VERSION ""

NS_ :

BS_:

BU_: Amperes VoltTemp_7 VoltTemp_6 VoltTemp_5 VoltTemp_4 VoltTemp_3 VoltTemp_2 VoltTemp_1 VoltTemp_0 BPS_Leader
VAL_TABLE_ BPS_Fault_Type 16 "Discharging Overcurrent" 15 "Charging Overcurrent" 14 "Estop 3" 13 "Estop 2" 12 "Estop 1" 11 "Array Pchg Contactor Sense" 10 "Array Contactor Sense" 9 "HV Minus Contactor Sense" 8 "HV Plus Contactor Sense" 7 "Watchdog" 6 "Array Precharge Timeout" 5 "Elcon" 4 "Overtemperature" 3 "Regen" 2 "Undervoltage" 1 "Overvoltage" 0 "No Fault" ;

BO_ 3221225472 VECTOR__INDEPENDENT_SIG_MSG: 0 Vector__XXX
 SG_ BPS_VoltTemp_ID : 0|3@1+ (1,0) [0|7] "" Vector__XXX
 SG_ BPS_Tap_idx : 0|5@1+ (1,0) [0|31] "" Vector__XXX
 SG_ BPS_VoltTemp_ID : 0|3@1+ (1,0) [0|7] "" Vector__XXX
 SG_ BPS_Temperature_Tap_Fault : 0|1@1+ (1,0) [0|0] "" Vector__XXX
 SG_ BPS_VoltTemp_BQ_Fault : 0|1@1+ (1,0) [0|0] "" Vector__XXX
 SG_ BPS_Temperature_Tap_RawV : 0|16@1+ (0.001,0) [0|65.535] "V" Vector__XXX
 SG_ BPS_Temperature_Tap_Data : 0|16@1- (0.01,0) [-327.68|327.67] "C" Vector__XXX
 SG_ BPS_Voltage_Tap_Data : 0|16@1+ (0.001,0) [0|65.535] "V" Vector__XXX
 SG_ BPS_Tap_idx : 0|5@1+ (1,0) [0|31] "" Vector__XXX
 SG_ BPS_Temperature_Tap_Fault : 0|1@1+ (1,0) [0|0] "" Vector__XXX
 SG_ BPS_VoltTemp_BQ_Fault : 0|1@1+ (1,0) [0|0] "" Vector__XXX
 SG_ BPS_Temperature_Tap_RawV : 0|16@1+ (0.001,0) [0|65.535] "V" Vector__XXX
 SG_ BPS_Temperature_Tap_Data : 0|16@1- (0.01,0) [-327.68|327.67] "C" Vector__XXX
 SG_ BPS_Voltage_Tap_Data : 0|16@1+ (0.001,0) [0|65.535] "V" Vector__XXX
 SG_ BPS_Tap_idx : 0|5@1+ (1,0) [0|31] "" Vector__XXX
 SG_ BPS_Temperature_Tap_Fault : 0|1@1+ (1,0) [0|0] "" Vector__XXX
 SG_ BPS_VoltTemp_BQ_Fault : 0|1@1+ (1,0) [0|0] "" Vector__XXX
 SG_ BPS_Temperature_Tap_RawV : 0|16@1+ (0.001,0) [0|65.535] "V" Vector__XXX
 SG_ BPS_Temperature_Tap_Data : 0|16@1- (0.01,0) [-327.68|327.67] "C" Vector__XXX
 SG_ BPS_Voltage_Tap_Data : 0|16@1+ (0.001,0) [0|65.535] "V" Vector__XXX
 SG_ BPS_Tap_idx : 0|5@1+ (1,0) [0|31] "" Vector__XXX
 SG_ BPS_Temperature_Tap_Fault : 0|1@1+ (1,0) [0|0] "" Vector__XXX
 SG_ BPS_VoltTemp_BQ_Fault : 0|1@1+ (1,0) [0|0] "" Vector__XXX
 SG_ BPS_Temperature_Tap_RawV : 0|16@1+ (0.001,0) [0|65.535] "V" Vector__XXX
 SG_ BPS_Temperature_Tap_Data : 0|16@1- (0.01,0) [-327.68|327.67] "C" Vector__XXX
 SG_ BPS_Voltage_Tap_Data : 0|16@1+ (0.001,0) [0|65.535] "V" Vector__XXX
 SG_ BPS_Tap_idx : 0|5@1+ (1,0) [0|31] "" Vector__XXX
 SG_ BPS_Temperature_Tap_Fault : 0|1@1+ (1,0) [0|0] "" Vector__XXX
 SG_ BPS_VoltTemp_BQ_Fault : 0|1@1+ (1,0) [0|0] "" Vector__XXX
 SG_ BPS_Temperature_Tap_RawV : 0|16@1+ (0.001,0) [0|65.535] "V" Vector__XXX
 SG_ BPS_Temperature_Tap_Data : 0|16@1- (0.01,0) [-327.68|327.67] "C" Vector__XXX
 SG_ BPS_Voltage_Tap_Data : 0|16@1+ (0.001,0) [0|65.535] "V" Vector__XXX
 SG_ BPS_Tap_idx : 0|5@1+ (1,0) [0|31] "" Vector__XXX
 SG_ BPS_Temperature_Tap_Fault : 0|1@1+ (1,0) [0|0] "" Vector__XXX
 SG_ BPS_VoltTemp_BQ_Fault : 0|1@1+ (1,0) [0|0] "" Vector__XXX
 SG_ BPS_Temperature_Tap_RawV : 0|16@1+ (0.001,0) [0|65.535] "V" Vector__XXX
 SG_ BPS_Temperature_Tap_Data : 0|16@1- (0.01,0) [-327.68|327.67] "C" Vector__XXX
 SG_ BPS_Voltage_Tap_Data : 0|16@1+ (0.001,0) [0|65.535] "V" Vector__XXX
 SG_ BPS_Tap_idx : 0|5@1+ (1,0) [0|31] "" Vector__XXX
 SG_ BPS_Temperature_Tap_Fault : 0|1@1+ (1,0) [0|0] "" Vector__XXX
 SG_ BPS_VoltTemp_BQ_Fault : 0|1@1+ (1,0) [0|0] "" Vector__XXX
 SG_ BPS_Temperature_Tap_RawV : 0|16@1+ (0.001,0) [0|65.535] "V" Vector__XXX
 SG_ BPS_Temperature_Tap_Data : 0|16@1- (0.01,0) [-327.68|327.67] "C" Vector__XXX
 SG_ BPS_Voltage_Tap_Data : 0|16@1+ (0.001,0) [0|65.535] "V" Vector__XXX
 SG_ BPS_Tap_idx : 0|5@1+ (1,0) [0|31] "" Vector__XXX

BO_ 23 BPS_Temperature_Arr_7: 6 Vector__XXX
 SG_ BPS_Temperature_Tap_Fault : 5|3@1+ (1,0) [0|0] "" Vector__XXX
 SG_ BPS_Temperature_Tap_RawV : 40|16@1+ (0.001,0) [0|65.535] "V" Vector__XXX
 SG_ BPS_Temperature_Tap_Data : 8|32@1- (0.001,0) [-2147483.648|2147483.647] "C" Vector__XXX
 SG_ BPS_Tap_idx : 0|5@1+ (1,0) [0|31] "" Vector__XXX

BO_ 22 BPS_Temperature_Arr_6: 6 Vector__XXX
 SG_ BPS_Temperature_Tap_Fault : 5|3@1+ (1,0) [0|0] "" Vector__XXX
 SG_ BPS_Temperature_Tap_RawV : 40|16@1+ (0.001,0) [0|65.535] "V" Vector__XXX
 SG_ BPS_Temperature_Tap_Data : 8|32@1- (0.001,0) [-2147483.648|2147483.647] "C" Vector__XXX
 SG_ BPS_Tap_idx : 0|5@1+ (1,0) [0|31] "" Vector__XXX

BO_ 21 BPS_Temperature_Arr_5: 6 Vector__XXX
 SG_ BPS_Temperature_Tap_Fault : 5|3@1+ (1,0) [0|0] "" Vector__XXX
 SG_ BPS_Temperature_Tap_RawV : 40|16@1+ (0.001,0) [0|65.535] "V" Vector__XXX
 SG_ BPS_Temperature_Tap_Data : 8|32@1- (0.001,0) [-2147483.648|2147483.647] "C" Vector__XXX
 SG_ BPS_Tap_idx : 0|5@1+ (1,0) [0|31] "" Vector__XXX

BO_ 20 BPS_Temperature_Arr_4: 6 Vector__XXX
 SG_ BPS_Temperature_Tap_Fault : 5|3@1+ (1,0) [0|0] "" Vector__XXX
 SG_ BPS_Temperature_Tap_RawV : 40|16@1+ (0.001,0) [0|65.535] "V" Vector__XXX
 SG_ BPS_Temperature_Tap_Data : 8|32@1- (0.001,0) [-2147483.648|2147483.647] "C" Vector__XXX
 SG_ BPS_Tap_idx : 0|5@1+ (1,0) [0|31] "" Vector__XXX

BO_ 19 BPS_Temperature_Arr_3: 6 Vector__XXX
 SG_ BPS_Temperature_Tap_Fault : 5|3@1+ (1,0) [0|0] "" Vector__XXX
 SG_ BPS_Temperature_Tap_RawV : 40|16@1+ (0.001,0) [0|65.535] "V" Vector__XXX
 SG_ BPS_Temperature_Tap_Data : 8|32@1- (0.001,0) [-2147483.648|2147483.647] "C" Vector__XXX
 SG_ BPS_Tap_idx : 0|5@1+ (1,0) [0|31] "" Vector__XXX

BO_ 18 BPS_Temperature_Arr_2: 6 Vector__XXX
 SG_ BPS_Temperature_Tap_Fault : 5|3@1+ (1,0) [0|0] "" Vector__XXX
 SG_ BPS_Temperature_Tap_RawV : 40|16@1+ (0.001,0) [0|65.535] "V" Vector__XXX
 SG_ BPS_Temperature_Tap_Data : 8|32@1- (0.001,0) [-2147483.648|2147483.647] "C" Vector__XXX
 SG_ BPS_Tap_idx : 0|5@1+ (1,0) [0|31] "" Vector__XXX

BO_ 17 BPS_Temperature_Arr_1: 6 Vector__XXX
 SG_ BPS_Temperature_Tap_Fault : 5|3@1+ (1,0) [0|0] "" Vector__XXX
 SG_ BPS_Temperature_Tap_RawV : 40|16@1+ (0.001,0) [0|65.535] "V" Vector__XXX
 SG_ BPS_Temperature_Tap_Data : 8|32@1- (0.001,0) [-2147483.648|2147483.647] "C" Vector__XXX
 SG_ BPS_Tap_idx : 0|5@1+ (1,0) [0|31] "" Vector__XXX

BO_ 16 BPS_Temperature_Arr_0: 6 Vector__XXX
 SG_ BPS_Temperature_Tap_Fault : 5|3@1+ (1,0) [0|0] "" Vector__XXX
 SG_ BPS_Temperature_Tap_RawV : 40|16@1+ (0.001,0) [0|65.535] "V" Vector__XXX
 SG_ BPS_Temperature_Tap_Data : 8|32@1- (0.001,0) [-2147483.648|2147483.647] "C" Vector__XXX
 SG_ BPS_Tap_idx : 0|5@1+ (1,0) [0|31] "" Vector__XXX

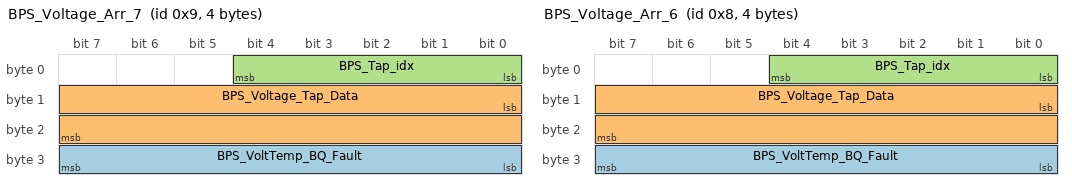
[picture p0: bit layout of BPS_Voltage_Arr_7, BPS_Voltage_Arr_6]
BO_ 9 BPS_Voltage_Arr_7: 4 Vector__XXX
 SG_ BPS_VoltTemp_BQ_Fault : 24|8@1+ (1,0) [0|0] "" Vector__XXX
 SG_ BPS_Voltage_Tap_Data : 8|16@1+ (0.001,0) [0|65.535] "V" Vector__XXX
 SG_ BPS_Tap_idx : 0|5@1+ (1,0) [0|31] "" Vector__XXX

BO_ 8 BPS_Voltage_Arr_6: 4 Vector__XXX
 SG_ BPS_VoltTemp_BQ_Fault : 24|8@1+ (1,0) [0|0] "" Vector__XXX
 SG_ BPS_Voltage_Tap_Data : 8|16@1+ (0.001,0) [0|65.535] "V" Vector__XXX
 SG_ BPS_Tap_idx : 0|5@1+ (1,0) [0|31] "" Vector__XXX

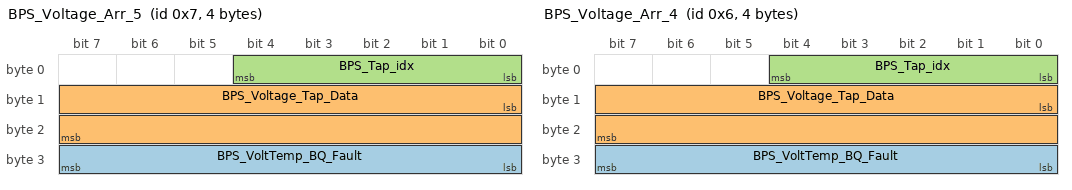
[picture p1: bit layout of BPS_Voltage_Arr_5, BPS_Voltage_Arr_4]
BO_ 7 BPS_Voltage_Arr_5: 4 Vector__XXX
 SG_ BPS_VoltTemp_BQ_Fault : 24|8@1+ (1,0) [0|0] "" Vector__XXX
 SG_ BPS_Voltage_Tap_Data : 8|16@1+ (0.001,0) [0|65.535] "V" Vector__XXX
 SG_ BPS_Tap_idx : 0|5@1+ (1,0) [0|31] "" Vector__XXX

BO_ 6 BPS_Voltage_Arr_4: 4 Vector__XXX
 SG_ BPS_VoltTemp_BQ_Fault : 24|8@1+ (1,0) [0|0] "" Vector__XXX
 SG_ BPS_Voltage_Tap_Data : 8|16@1+ (0.001,0) [0|65.535] "V" Vector__XXX
 SG_ BPS_Tap_idx : 0|5@1+ (1,0) [0|31] "" Vector__XXX

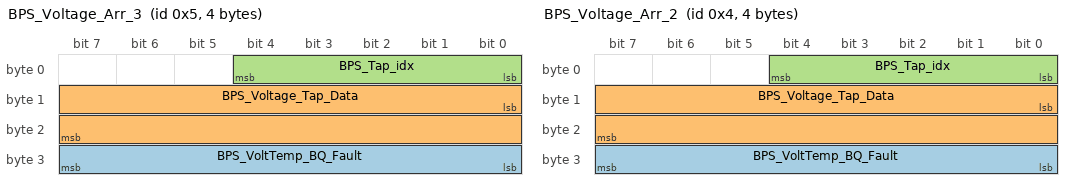
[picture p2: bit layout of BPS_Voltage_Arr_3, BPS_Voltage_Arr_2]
BO_ 5 BPS_Voltage_Arr_3: 4 Vector__XXX
 SG_ BPS_VoltTemp_BQ_Fault : 24|8@1+ (1,0) [0|0] "" Vector__XXX
 SG_ BPS_Voltage_Tap_Data : 8|16@1+ (0.001,0) [0|65.535] "V" Vector__XXX
 SG_ BPS_Tap_idx : 0|5@1+ (1,0) [0|31] "" Vector__XXX

BO_ 4 BPS_Voltage_Arr_2: 4 Vector__XXX
 SG_ BPS_VoltTemp_BQ_Fault : 24|8@1+ (1,0) [0|0] "" Vector__XXX
 SG_ BPS_Voltage_Tap_Data : 8|16@1+ (0.001,0) [0|65.535] "V" Vector__XXX
 SG_ BPS_Tap_idx : 0|5@1+ (1,0) [0|31] "" Vector__XXX

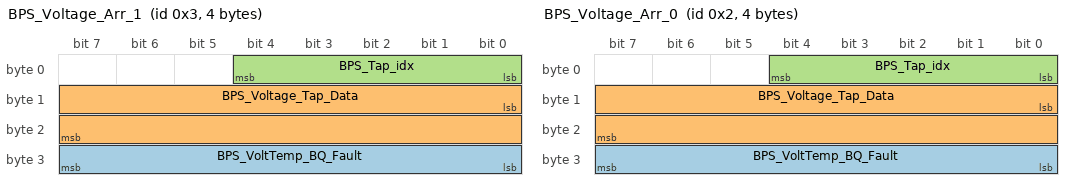
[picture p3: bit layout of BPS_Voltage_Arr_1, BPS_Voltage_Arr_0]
BO_ 3 BPS_Voltage_Arr_1: 4 Vector__XXX
 SG_ BPS_VoltTemp_BQ_Fault : 24|8@1+ (1,0) [0|0] "" Vector__XXX
 SG_ BPS_Voltage_Tap_Data : 8|16@1+ (0.001,0) [0|65.535] "V" Vector__XXX
 SG_ BPS_Tap_idx : 0|5@1+ (1,0) [0|31] "" Vector__XXX

BO_ 32 BPS_Precharge_Voltages: 6 BPS_Leader
 SG_ Precharge_Battery_Voltage : 0|24@1+ (0.001,0) [0|16777.215] "V" Vector__XXX
 SG_ Precharge_Array_Voltage : 24|24@1+ (0.001,0) [0|16777.215] "V" Vector__XXX

BO_ 2 BPS_Voltage_Arr_0: 4 VoltTemp_0
 SG_ BPS_VoltTemp_BQ_Fault : 24|8@1+ (1,0) [0|0] "" Vector__XXX
 SG_ BPS_Voltage_Tap_Data : 8|16@1+ (0.001,0) [0|65.535] "V" Vector__XXX
 SG_ BPS_Tap_idx : 0|5@1+ (1,0) [0|31] "" Vector__XXX

BO_ 10 BPS_Pack_Current: 5 Amperes
 SG_ Main_Battery_Current_RawV : 24|16@1+ (0.001,0) [0|65.535] "V" Vector__XXX
 SG_ Main_Battery_Current : 0|24@1- (0.001,0) [-8388.608|8388.607] "A" Vector__XXX

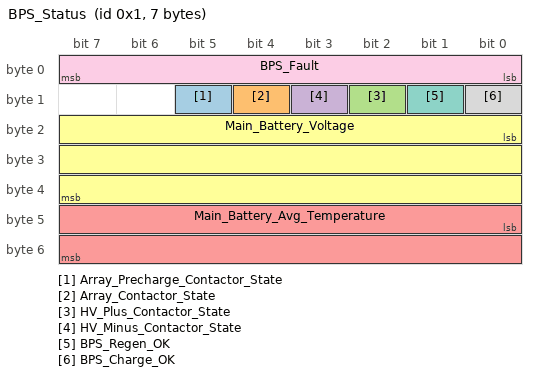
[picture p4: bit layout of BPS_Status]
BO_ 1 BPS_Status: 7 BPS_Leader
 SG_ Array_Precharge_Contactor_State : 13|1@1+ (1,0) [0|0] "" Vector__XXX
 SG_ Array_Contactor_State : 12|1@1+ (1,0) [0|0] "" Vector__XXX
 SG_ HV_Plus_Contactor_State : 10|1@1+ (1,0) [0|0] "" Vector__XXX
 SG_ HV_Minus_Contactor_State : 11|1@1+ (1,0) [0|0] "" Vector__XXX
 SG_ Main_Battery_Avg_Temperature : 40|16@1- (0.01,0) [-327.68|327.67] "" Vector__XXX
 SG_ Main_Battery_Voltage : 16|24@1+ (0.001,0) [0|16777.215] "V" Vector__XXX
 SG_ BPS_Regen_OK : 9|1@1+ (1,0) [0|0] "" Vector__XXX
 SG_ BPS_Charge_OK : 8|1@1+ (1,0) [0|0] "" Vector__XXX
 SG_ BPS_Fault : 0|8@1+ (1,0) [0|0] "" Vector__XXX

CM_ BO_ 3221225472 "This is a message for not used signals, created by Vector CANdb++ DBC OLE DB Provider.";
CM_ SG_ 3221225472 BPS_VoltTemp_ID "BPS VoltTemp IDBPS VoltTemp ID";
CM_ SG_ 3221225472 BPS_Tap_idx "BPS Voltage/Temperature Tap ID (4 taps per VoltTemp)";
CM_ SG_ 3221225472 BPS_Temperature_Tap_Fault "VoltTemp Temperature Tap Fault State (0 no fault, 1 fault)";
CM_ SG_ 3221225472 BPS_VoltTemp_BQ_Fault "VoltTemp BQ Fault State (0 no fault, 1 fault)";
CM_ SG_ 3221225472 BPS_Temperature_Tap_RawV "Raw thermistor voltage measurement for the specified VoltTemp and Tap ID";
CM_ SG_ 3221225472 BPS_Temperature_Tap_Data "Temperature tap measurement for the specified VoltTemp and Tap ID";
CM_ SG_ 3221225472 BPS_Voltage_Tap_Data "Voltage tap measurement for the specified VoltTemp and Tap ID";
CM_ SG_ 3221225472 BPS_Tap_idx "BPS Voltage/Temperature Tap ID (4 taps per VoltTemp)";
CM_ SG_ 3221225472 BPS_Temperature_Tap_Fault "VoltTemp Temperature Tap Fault State (0 no fault, 1 fault)";
CM_ SG_ 3221225472 BPS_VoltTemp_BQ_Fault "VoltTemp BQ Fault State (0 no fault, 1 fault)";
CM_ SG_ 3221225472 BPS_Temperature_Tap_RawV "Raw thermistor voltage measurement for the specified VoltTemp and Tap ID";
CM_ SG_ 3221225472 BPS_Temperature_Tap_Data "Temperature tap measurement for the specified VoltTemp and Tap ID";
CM_ SG_ 3221225472 BPS_Voltage_Tap_Data "Voltage tap measurement for the specified VoltTemp and Tap ID";
CM_ SG_ 3221225472 BPS_Tap_idx "BPS Voltage/Temperature Tap ID (4 taps per VoltTemp)";
CM_ SG_ 3221225472 BPS_Temperature_Tap_Fault "VoltTemp Temperature Tap Fault State (0 no fault, 1 fault)";
CM_ SG_ 3221225472 BPS_VoltTemp_BQ_Fault "VoltTemp BQ Fault State (0 no fault, 1 fault)";
CM_ SG_ 3221225472 BPS_Temperature_Tap_RawV "Raw thermistor voltage measurement for the specified VoltTemp and Tap ID";
CM_ SG_ 3221225472 BPS_Temperature_Tap_Data "Temperature tap measurement for the specified VoltTemp and Tap ID";
CM_ SG_ 3221225472 BPS_Voltage_Tap_Data "Voltage tap measurement for the specified VoltTemp and Tap ID";
CM_ SG_ 3221225472 BPS_Tap_idx "BPS Voltage/Temperature Tap ID (4 taps per VoltTemp)";
CM_ SG_ 3221225472 BPS_Temperature_Tap_Fault "VoltTemp Temperature Tap Fault State (0 no fault, 1 fault)";
CM_ SG_ 3221225472 BPS_VoltTemp_BQ_Fault "VoltTemp BQ Fault State (0 no fault, 1 fault)";
CM_ SG_ 3221225472 BPS_Temperature_Tap_RawV "Raw thermistor voltage measurement for the specified VoltTemp and Tap ID";
CM_ SG_ 3221225472 BPS_Temperature_Tap_Data "Temperature tap measurement for the specified VoltTemp and Tap ID";
CM_ SG_ 3221225472 BPS_Voltage_Tap_Data "Voltage tap measurement for the specified VoltTemp and Tap ID";
CM_ SG_ 3221225472 BPS_Tap_idx "BPS Voltage/Temperature Tap ID (4 taps per VoltTemp)";
CM_ SG_ 3221225472 BPS_Temperature_Tap_Fault "VoltTemp Temperature Tap Fault State (0 no fault, 1 fault)";
CM_ SG_ 3221225472 BPS_VoltTemp_BQ_Fault "VoltTemp BQ Fault State (0 no fault, 1 fault)";
CM_ SG_ 3221225472 BPS_Temperature_Tap_RawV "Raw thermistor voltage measurement for the specified VoltTemp and Tap ID";
CM_ SG_ 3221225472 BPS_Temperature_Tap_Data "Temperature tap measurement for the specified VoltTemp and Tap ID";
CM_ SG_ 3221225472 BPS_Voltage_Tap_Data "Voltage tap measurement for the specified VoltTemp and Tap ID";
CM_ SG_ 3221225472 BPS_Tap_idx "BPS Voltage/Temperature Tap ID (4 taps per VoltTemp)";
CM_ SG_ 3221225472 BPS_Temperature_Tap_Fault "VoltTemp Temperature Tap Fault State (0 no fault, 1 fault)";
CM_ SG_ 3221225472 BPS_VoltTemp_BQ_Fault "VoltTemp BQ Fault State (0 no fault, 1 fault)";
CM_ SG_ 3221225472 BPS_Temperature_Tap_RawV "Raw thermistor voltage measurement for the specified VoltTemp and Tap ID";
CM_ SG_ 3221225472 BPS_Temperature_Tap_Data "Temperature tap measurement for the specified VoltTemp and Tap ID";
CM_ SG_ 3221225472 BPS_Voltage_Tap_Data "Voltage tap measurement for the specified VoltTemp and Tap ID";
CM_ SG_ 3221225472 BPS_Tap_idx "BPS Voltage/Temperature Tap ID (4 taps per VoltTemp)";
CM_ SG_ 3221225472 BPS_Temperature_Tap_Fault "VoltTemp Temperature Tap Fault State (0 no fault, 1 fault)";
CM_ SG_ 3221225472 BPS_VoltTemp_BQ_Fault "VoltTemp BQ Fault State (0 no fault, 1 fault)";
CM_ SG_ 3221225472 BPS_Temperature_Tap_RawV "Raw thermistor voltage measurement for the specified VoltTemp and Tap ID";
CM_ SG_ 3221225472 BPS_Temperature_Tap_Data "Temperature tap measurement for the specified VoltTemp and Tap ID";
CM_ SG_ 3221225472 BPS_Voltage_Tap_Data "Voltage tap measurement for the specified VoltTemp and Tap ID";
CM_ SG_ 3221225472 BPS_Tap_idx "BPS Voltage/Temperature Tap ID (4 taps per VoltTemp)";
CM_ SG_ 23 BPS_Temperature_Tap_Fault "VoltTemp Temperature Tap Fault State (0 no fault, 1 fault)";
CM_ SG_ 23 BPS_Temperature_Tap_RawV "Raw thermistor voltage measurement for the specified VoltTemp and Tap ID";
CM_ SG_ 23 BPS_Temperature_Tap_Data "Temperature tap measurement for the specified VoltTemp and Tap ID";
CM_ SG_ 23 BPS_Tap_idx "BPS Voltage/Temperature Tap ID (4 taps per VoltTemp)";
CM_ SG_ 22 BPS_Temperature_Tap_Fault "VoltTemp Temperature Tap Fault State (0 no fault, 1 fault)";
CM_ SG_ 22 BPS_Temperature_Tap_RawV "Raw thermistor voltage measurement for the specified VoltTemp and Tap ID";
CM_ SG_ 22 BPS_Temperature_Tap_Data "Temperature tap measurement for the specified VoltTemp and Tap ID";
CM_ SG_ 22 BPS_Tap_idx "BPS Voltage/Temperature Tap ID (4 taps per VoltTemp)";
CM_ SG_ 21 BPS_Temperature_Tap_Fault "VoltTemp Temperature Tap Fault State (0 no fault, 1 fault)";
CM_ SG_ 21 BPS_Temperature_Tap_RawV "Raw thermistor voltage measurement for the specified VoltTemp and Tap ID";
CM_ SG_ 21 BPS_Temperature_Tap_Data "Temperature tap measurement for the specified VoltTemp and Tap ID";
CM_ SG_ 21 BPS_Tap_idx "BPS Voltage/Temperature Tap ID (4 taps per VoltTemp)";
CM_ SG_ 20 BPS_Temperature_Tap_Fault "VoltTemp Temperature Tap Fault State (0 no fault, 1 fault)";
CM_ SG_ 20 BPS_Temperature_Tap_RawV "Raw thermistor voltage measurement for the specified VoltTemp and Tap ID";
CM_ SG_ 20 BPS_Temperature_Tap_Data "Temperature tap measurement for the specified VoltTemp and Tap ID";
CM_ SG_ 20 BPS_Tap_idx "BPS Voltage/Temperature Tap ID (4 taps per VoltTemp)";
CM_ SG_ 19 BPS_Temperature_Tap_Fault "VoltTemp Temperature Tap Fault State (0 no fault, 1 fault)";
CM_ SG_ 19 BPS_Temperature_Tap_RawV "Raw thermistor voltage measurement for the specified VoltTemp and Tap ID";
CM_ SG_ 19 BPS_Temperature_Tap_Data "Temperature tap measurement for the specified VoltTemp and Tap ID";
CM_ SG_ 19 BPS_Tap_idx "BPS Voltage/Temperature Tap ID (4 taps per VoltTemp)";
CM_ SG_ 18 BPS_Temperature_Tap_Fault "VoltTemp Temperature Tap Fault State (0 no fault, 1 fault)";
CM_ SG_ 18 BPS_Temperature_Tap_RawV "Raw thermistor voltage measurement for the specified VoltTemp and Tap ID";
CM_ SG_ 18 BPS_Temperature_Tap_Data "Temperature tap measurement for the specified VoltTemp and Tap ID";
CM_ SG_ 18 BPS_Tap_idx "BPS Voltage/Temperature Tap ID (4 taps per VoltTemp)";
CM_ SG_ 17 BPS_Temperature_Tap_Fault "VoltTemp Temperature Tap Fault State (0 no fault, 1 fault)";
CM_ SG_ 17 BPS_Temperature_Tap_RawV "Raw thermistor voltage measurement for the specified VoltTemp and Tap ID";
CM_ SG_ 17 BPS_Temperature_Tap_Data "Temperature tap measurement for the specified VoltTemp and Tap ID";
CM_ SG_ 17 BPS_Tap_idx "BPS Voltage/Temperature Tap ID (4 taps per VoltTemp)";
CM_ SG_ 16 BPS_Temperature_Tap_Fault "VoltTemp Temperature Tap Fault State (0 no fault, 1 fault)";
CM_ SG_ 16 BPS_Temperature_Tap_RawV "Raw thermistor voltage measurement for the specified VoltTemp and Tap ID";
CM_ SG_ 16 BPS_Temperature_Tap_Data "Temperature tap measurement for the specified VoltTemp and Tap ID";
CM_ SG_ 16 BPS_Tap_idx "BPS Voltage/Temperature Tap ID (4 taps per VoltTemp)";
CM_ SG_ 9 BPS_VoltTemp_BQ_Fault "VoltTemp BQ Fault State (0 no fault, 1 fault)";
CM_ SG_ 9 BPS_Voltage_Tap_Data "Voltage tap measurement for the specified VoltTemp and Tap ID";
CM_ SG_ 9 BPS_Tap_idx "BPS Voltage/Temperature Tap ID (4 taps per VoltTemp)";
CM_ SG_ 8 BPS_VoltTemp_BQ_Fault "VoltTemp BQ Fault State (0 no fault, 1 fault)";
CM_ SG_ 8 BPS_Voltage_Tap_Data "Voltage tap measurement for the specified VoltTemp and Tap ID";
CM_ SG_ 8 BPS_Tap_idx "BPS Voltage/Temperature Tap ID (4 taps per VoltTemp)";
CM_ SG_ 7 BPS_VoltTemp_BQ_Fault "VoltTemp BQ Fault State (0 no fault, 1 fault)";
CM_ SG_ 7 BPS_Voltage_Tap_Data "Voltage tap measurement for the specified VoltTemp and Tap ID";
CM_ SG_ 7 BPS_Tap_idx "BPS Voltage/Temperature Tap ID (4 taps per VoltTemp)";
CM_ SG_ 6 BPS_VoltTemp_BQ_Fault "VoltTemp BQ Fault State (0 no fault, 1 fault)";
CM_ SG_ 6 BPS_Voltage_Tap_Data "Voltage tap measurement for the specified VoltTemp and Tap ID";
CM_ SG_ 6 BPS_Tap_idx "BPS Voltage/Temperature Tap ID (4 taps per VoltTemp)";
CM_ SG_ 5 BPS_VoltTemp_BQ_Fault "VoltTemp BQ Fault State (0 no fault, 1 fault)";
CM_ SG_ 5 BPS_Voltage_Tap_Data "Voltage tap measurement for the specified VoltTemp and Tap ID";
CM_ SG_ 5 BPS_Tap_idx "BPS Voltage/Temperature Tap ID (4 taps per VoltTemp)";
CM_ SG_ 4 BPS_VoltTemp_BQ_Fault "VoltTemp BQ Fault State (0 no fault, 1 fault)";
CM_ SG_ 4 BPS_Voltage_Tap_Data "Voltage tap measurement for the specified VoltTemp and Tap ID";
CM_ SG_ 4 BPS_Tap_idx "BPS Voltage/Temperature Tap ID (4 taps per VoltTemp)";
CM_ SG_ 3 BPS_VoltTemp_BQ_Fault "VoltTemp BQ Fault State (0 no fault, 1 fault)";
CM_ SG_ 3 BPS_Voltage_Tap_Data "Voltage tap measurement for the specified VoltTemp and Tap ID";
CM_ SG_ 3 BPS_Tap_idx "BPS Voltage/Temperature Tap ID (4 taps per VoltTemp)";
CM_ SG_ 32 Precharge_Battery_Voltage "Battery voltage as measured by active precharge circuitry";
CM_ SG_ 32 Precharge_Array_Voltage "Array voltage as measured by active precharge circuitry";
CM_ SG_ 2 BPS_VoltTemp_BQ_Fault "VoltTemp BQ Fault State (0 no fault, 1 fault)";
CM_ SG_ 2 BPS_Voltage_Tap_Data "Voltage tap measurement for the specified VoltTemp and Tap ID";
CM_ SG_ 2 BPS_Tap_idx "BPS Voltage/Temperature Tap ID (4 taps per VoltTemp)";
CM_ SG_ 10 Main_Battery_Current_RawV "Main battery current raw voltage as measured by the BPS";
CM_ SG_ 10 Main_Battery_Current "Main battery current as measured by the BPS";
CM_ SG_ 1 Array_Precharge_Contactor_State "Array Precharge Contactor State (0 open, 1 closed)";
CM_ SG_ 1 Array_Contactor_State "Array Main Contactor State (0 open, 1 closed)";
CM_ SG_ 1 HV_Plus_Contactor_State "HV+ Contactor State (0 open, 1 closed)";
CM_ SG_ 1 HV_Minus_Contactor_State "HV- Contactor State (0 open, 1 closed)";
CM_ SG_ 1 Main_Battery_Avg_Temperature "Average pack temperature as determined by the BPS";
CM_ SG_ 1 Main_Battery_Voltage "Total battery pack voltage as determined by the BPS";
CM_ SG_ 1 BPS_Regen_OK "BPS has determined regenerative braking is OK (0 not ok, 1 ok)";
CM_ SG_ 1 BPS_Charge_OK "BPS has determined charging the pack is OK (0 not ok, 1 ok)";
CM_ SG_ 1 BPS_Fault "BPS Fault State (0 for all clear; see value table for specific faults)";
BA_DEF_  "DatabaseVersion" STRING ;
BA_DEF_ BO_  "VFrameFormat" ENUM  "StandardCAN","ExtendedCAN","reserved","J1939PG";
BA_DEF_  "BusType" STRING ;
BA_DEF_DEF_  "DatabaseVersion" "DEMO PLUS";
BA_DEF_DEF_  "VFrameFormat" "J1939PG";
BA_DEF_DEF_  "BusType" "";
BA_ "BusType" "CAN";
BA_ "VFrameFormat" BO_ 23 0;
BA_ "VFrameFormat" BO_ 22 0;
BA_ "VFrameFormat" BO_ 21 0;
BA_ "VFrameFormat" BO_ 20 0;
BA_ "VFrameFormat" BO_ 19 0;
BA_ "VFrameFormat" BO_ 18 0;
BA_ "VFrameFormat" BO_ 17 0;
BA_ "VFrameFormat" BO_ 16 0;
BA_ "VFrameFormat" BO_ 9 0;
BA_ "VFrameFormat" BO_ 8 0;
BA_ "VFrameFormat" BO_ 7 0;
BA_ "VFrameFormat" BO_ 6 0;
BA_ "VFrameFormat" BO_ 5 0;
BA_ "VFrameFormat" BO_ 4 0;
BA_ "VFrameFormat" BO_ 3 0;
BA_ "VFrameFormat" BO_ 32 0;
BA_ "VFrameFormat" BO_ 2 0;
BA_ "VFrameFormat" BO_ 10 0;
BA_ "VFrameFormat" BO_ 1 0;
VAL_ 1 BPS_Fault 16 "Discharging Overcurrent" 15 "Charging Overcurrent" 14 "Estop 3" 13 "Estop 2" 12 "Estop 1" 11 "Array Pchg Contactor Sense" 10 "Array Contactor Sense" 9 "HV- Contactor Sense" 8 "HV+ Contactor Sense" 7 "Watchdog" 6 "Array Precharge Timeout" 5 "Elcon" 4 "Overtemperature" 3 "Regen" 2 "Undervoltage" 1 "Overvoltage" 0 "No Fault" ;
